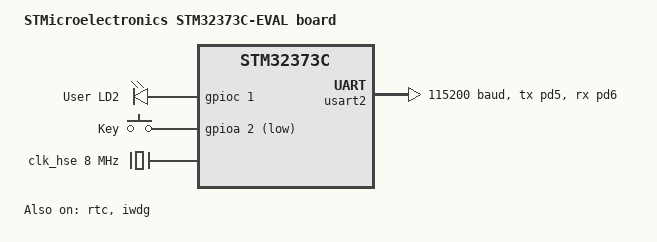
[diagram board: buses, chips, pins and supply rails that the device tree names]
/*
 * Copyright (c) 2017 Linaro Limited
 *
 * SPDX-License-Identifier: Apache-2.0
 */

/dts-v1/;
#include <st/f3/stm32f373Xc.dtsi>
#include <st/f3/stm32f373v(8-b-c)tx-pinctrl.dtsi>

/ {
	model = "STMicroelectronics STM32373C-EVAL board";
	compatible = "st,stm32373c-eval";

	chosen {
		zephyr,console = &usart2;
		zephyr,shell-uart = &usart2;
		zephyr,sram = &sram0;
		zephyr,flash = &flash0;
	};

	leds {
		compatible = "gpio-leds";
		green_led_2: led_2 {
			gpios = <&gpioc 1 GPIO_ACTIVE_HIGH>;
			label = "User LD2";
		};
	};

	gpio_keys {
		compatible = "gpio-keys";
		user_button: button {
			label = "Key";
			gpios = <&gpioa 2 GPIO_ACTIVE_LOW>;
		};
	};

	aliases {
		led0 = &green_led_2;
		sw0 = &user_button;
		watchdog0 = &iwdg;
	};
};

&clk_lsi {
	status = "okay";
};

&clk_hse {
	clock-frequency = <DT_FREQ_M(8)>;
	status = "okay";
};

&pll {
	prediv = <1>;
	mul = <9>;
	clocks = <&clk_hse>;
	status = "okay";
};

&rcc {
	clocks = <&pll>;
	clock-frequency = <DT_FREQ_M(72)>;
	ahb-prescaler = <1>;
	apb1-prescaler = <2>;
	apb2-prescaler = <2>;
};

&usart2 {
	pinctrl-0 = <&usart2_tx_pd5 &usart2_rx_pd6>;
	pinctrl-names = "default";
	current-speed = <115200>;
	status = "okay";
};

&rtc {
	clocks = <&rcc STM32_CLOCK_BUS_APB1 0x10000000>,
		 <&rcc STM32_SRC_LSI RTC_SEL(2)>;
	status = "okay";
};

&iwdg {
	status = "okay";
};
